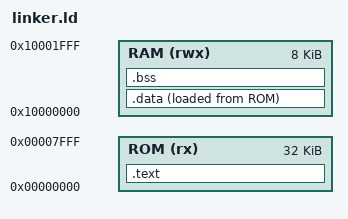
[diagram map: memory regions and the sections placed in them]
OUTPUT_ARCH(riscv)
ENTRY(_start)

MEMORY
{
    ROM (rx)  : ORIGIN = 0x00000000, LENGTH = 32K
    RAM (rwx) : ORIGIN = 0x10000000, LENGTH = 8K
}

SECTIONS
{
    .text : {
        KEEP(*(.text.start))
        *(.text*)
        *(.rodata*)
    } > ROM

    .data : ALIGN(4) {
        __data_start = .;
        *(.data*)
        . = ALIGN(4);
        __data_end = .;
    } > RAM AT > ROM
    __data_load_start = LOADADDR(.data);

    .bss (NOLOAD) : ALIGN(4) {
        __bss_start = .;
        *(.bss*)
        *(COMMON)
        . = ALIGN(4);
        __bss_end = .;
    } > RAM

    _stack_top = ORIGIN(RAM) + LENGTH(RAM);
}
